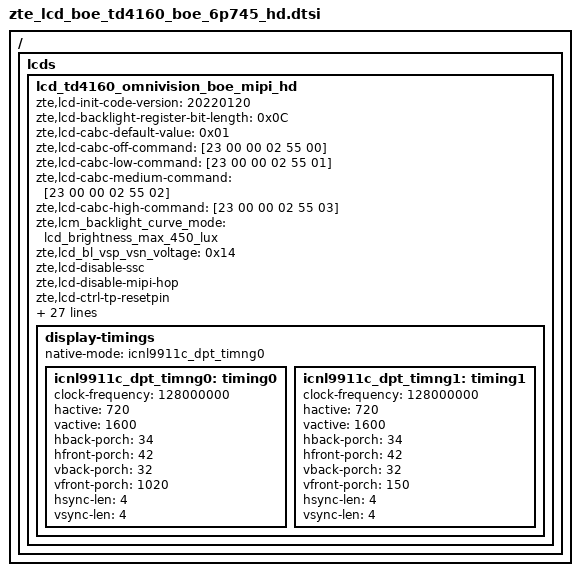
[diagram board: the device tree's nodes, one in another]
/ {
	fragment {
		target-path = "/";
		__overlay__ {
lcds {
		lcd_td4160_omnivision_boe_mipi_hd: lcd_td4160_omnivision_boe_mipi_hd {
			zte,lcd-init-code-version = "20220120";
			zte,lcd-backlight-register-bit-length = <0x0C>;
			zte,lcd-cabc-default-value = <0x01>;
			zte,lcd-cabc-off-command = [23 00 00 02 55 00];
			zte,lcd-cabc-low-command = [23 00 00 02 55 01];
			zte,lcd-cabc-medium-command = [23 00 00 02 55 02];
			zte,lcd-cabc-high-command = [23 00 00 02 55 03];
			zte,lcm_backlight_curve_mode = "lcd_brightness_max_450_lux";
			zte,lcd_bl_vsp_vsn_voltage = <0x14>;
			zte,lcd-disable-ssc;
			zte,lcd-disable-mipi-hop;
			zte,lcd-ctrl-tp-resetpin;
			zte,panel-name = "lcd_td4160_boe_6p745_mipi_hd_omnivision";
			zte,lcd-delay-open-bl-value = <30>;

			sprd,dsi-work-mode = <1>; /* video burst mode*/
			sprd,dsi-lane-number = <4>;
			sprd,dsi-color-format = "rgb888";

			sprd,phy-bit-clock = <768000>;	/* kbps */
			sprd,phy-escape-clock = <20000>;/* kHz */

			sprd,video-lp-cmd-enable = <1>;
			sprd,hporch-lp-disable = <1>;
			sprd,dpi-clk-div = <6>;

			sprd,width-mm = <70308>;
			sprd,height-mm = <156240>;

			sprd,esd-check-enable = <1>;/* 0:close , 1:open */
			sprd,esd-check-mode = <1>;/* 0:REG ,1:TE  */
			sprd,esd-check-period = <2000>;
			sprd,esd-check-register = <0x0A>;
			sprd,esd-check-value = <0x9C>;

			sprd,reset-on-sequence = <1 5>, <0 10>, <1 35>;
			sprd,reset-off-sequence = <0 5>;

			sprd,use-dcs-write;
			sprd,initial-command = [
				29 00 00 02 B0 04
				29 00 00 07 B6 30 6A 00 86 C3 03
				29 00 00 05 B7 31 00 00 00
				29 00 00 07 B8 00 78 64 10 64 B4
				29 00 00 07 B9 00 78 64 10 64 B4
				29 00 00 07 BA 07 7E 3E 10 1A 33
				29 00 00 04 BB 00 B4 A0
				29 00 00 04 BC 00 B4 A0
				29 00 00 04 BD 00 B4 A0
				29 00 00 0E BE 07 00 00 00 00 00 00 00 00
							00 00 00 00
				29 00 00 19 C0 00 60 24 06 40 00 16 06 98
							00 70 00 00 00 00 00 00 00 00
							00 00 00 00 00
				29 00 00 28 C1 30 11 50 FA 01 00 00 10 00
							00 00 00 40 0F 00 00 00 00 00
							00 00 00 00 00 00 00 00 00 00
							00 00 00 F0 07 08 07 D0 0A BE
				29 00 00 65 C2 01 20 50 14 04 10 0B 10 00
							00 00 00 00 00 00 00 00 00 00
							00 00 00 00 00 00 00 00 00 00
							00 00 00 00 00 00 00 00 00 00
							00 00 00 05 F0 54 08 08 05 05
							C5 00 80 00 00 00 00 08 00 00
							00 00 11 00 80 00 08 00 00 00
							00 00 00 00 00 00 00 00 00 00
							00 00 00 00 00 00 00 00 00 00
							00 00 00 00 11 00 00 00 00 00
							00
				29 00 00 65 C3 01 00 55 01 01 86 68 00 00
							00 20 01 01 00 55 01 01 86 68
							00 00 00 20 02 01 00 55 01 01
							86 68 00 00 00 20 00 01 00 55
							01 01 86 68 00 00 00 20 00 00
							00 00 08 00 00 00 00 00 00 00
							00 00 00 00 00 00 00 00 00 00
							00 00 00 00 00 00 00 00 00 00
							00 00 00 00 00 00 00 00 00 00
							00 00 00 00 00 00 00 00 00 00
							00
				29 00 00 55 C4 00 00 5E 64 00 03 05 13 15
							17 19 5D 5F 00 00 00 00 00 00
							00 00 00 00 00 00 00 00 00 00
							00 00 00 00 5F 5D 1A 18 16 14
							06 04 00 64 5E 00 00 00 00 00
							00 00 00 00 00 00 00 00 00 00
							00 00 00 00 00 00 00 00 00 00
							00 00 00 00 57 55 55 FF FF FF
							FF FF 55 55 D5
				29 00 00 06 C5 08 00 00 00 00
				29 00 00 4D C6 00 00 00 00 01 22 04 22 01
							00 61 00 00 00 01 00 61 00 01
							05 01 0B 01 35 FF 8F 06 05 01
							C0 0F 00 00 00 00 00 00 00 00
							00 00 00 00 00 00 00 00 00 00
							00 00 00 00 20 20 00 00 00 C0
							11 00 00 00 10 10 00 00 00 01
							00 50 00 33 03 00 00
				29 00 00 4D C7 00 00 00 79 00 B9 00 D3 00
							ED 00 FA 01 0A 01 0F 01 2E 01
							01 01 5C 01 22 01 6A 01 28 01
							99 01 A3 02 2D 02 96 02 A0 00
							00 00 79 00 B9 00 D3 00 ED 00
							FA 01 0A 01 0F 01 2E 01 01 01
							5C 01 22 01 6A 01 28 01 99 01
							A3 02 2D 02 96 02 A0
				29 00 00 1F CB 02 D0 01 80 00 00 00 00 00
							00 00 00 00 00 00 00 00 00 00
							00 00 00 40 70 00 00 00 00 00
							FF
				29 00 00 19 CE 5D 40 43 49 55 62 71 82 94
							A8 B9 CB DB E9 F5 FC FF 18 00
							04 04 00 04 8C
				29 00 00 02 CF 00
				29 00 00 15 D0 C1 46 81 66 09 90 00 CC F2
							FF 11 46 06 7E 09 08 CC 1B F0
							06
				29 00 00 26 D1 CE D8 1B 33 33 17 07 BB 33
							33 33 33 00 3B 77 07 3B 30 06
							72 33 13 00 D7 0C 33 02 00 18
							70 18 77 11 11 11 20 20
				29 00 00 04 D2 00 00 00
				29 00 00 65 D3 00 00 00 00 00 00 00 00 00
							FF F7 FF FF F7 FF FF F7 FF FF
							F7 FF FF F7 FF FF F7 FF FF F7
							FF FF F7 FF FF F7 FF FF F7 FF
							FF F7 FF FF F7 FF FF F7 FF FF
							F7 FF FF F7 FF FF F7 FF FF F7
							FF FF F7 FF FF F7 FF FF F7 FF
							FF F7 FF FF F7 FF FF F7 FF FF
							F7 FF FF F7 FF FF F7 FF FF F7
							FF FF F7 FF FF F7 FF FF F7 FF
							FF
				29 00 00 18 D4 00 00 00 00 00 00 00 00 00
							20 00 00 00 00 20 00 00 00 00
							00 00 00 00
				29 00 00 02 D6 00
				29 00 00 2F D7 01 00 12 12 00 62 00 16 00
							62 00 16 03 83 80 85 85 85 87
							84 45 86 87 80 88 86 89 83 83
							87 84 88 8A 0C 0B 0A 0A 0A 07
							07 06 06 00 08 0A 0A
				29 00 00 17 D8 40 99 26 ED 16 6C 16 6C 16
							6C 00 14 00 14 00 14 01 0C 00
							00 01 00
				29 00 00 29 D9 00 02 7F 00 00 00 00 00 00
							00 00 00 00 00 00 C0 00 00 00
							00 00 00 00 00 00 00 00 00 00
							00 00 00 00 00 00 00 00 00 00
							00
				29 00 00 05 DD 30 06 23 65
				29 00 00 0F DE 00 00 00 0F FF 00 00 00 00
							10 00 00 00 00
				29 00 00 05 E5 03 00 00 00
				29 00 00 09 E6 00 00 00 00 00 0E 00 00
				29 00 00 24 EA 02 07 07 04 80 10 01 00 00
							00 00 03 23 00 07 00 ED 00 ED
							00 ED 01 28 01 28 00 62 00 62
							00 62 01 0F 01 00
				29 00 00 09 EB 07 60 76 07 61 01 01 00
				29 00 00 18 EC 02 D0 01 70 73 10 01 00 00
							00 00 02 2A 00 00 00 00 00 00
							00 00 00 00
				29 00 00 22 ED 01 02 00 00 00 00 00 00 67
							A6 F0 00 00 00 00 00 00 00 00
							00 00 00 00 F0 01 00 00 00 00
							00 41 10 01
				29 00 00 65 EE 05 00 05 00 C0 0B 00 00 03
							00 00 03 00 00 03 00 C0 03 00
							00 00 00 00 00 03 00 00 00 00
							00 00 03 00 00 00 00 00 00 03
							00 00 00 00 00 00 03 00 40 17
							04 65 40 00 00 55 17 04 65 40
							00 00 55 17 04 65 40 00 00 40
							17 04 65 40 00 00 00 03 00 00
							03 00 00 03 00 00 03 00 00 03
							00 00 03 00 00 03 00 40 15 00
							00
				29 00 00 02 B0 03

				29 00 00 03 51 00 00
				29 00 00 02 53 2C
				29 00 00 02 55 00
				29 00 00 02 35 00

				05 78 00 01 11
				05 32 00 01 29
				];

			sprd,sleep-in-command = [
				15 0A 00 01 28
				15 78 00 01 10
				];

			sprd,sleep-out-command = [
				15 78 00 01 11
				15 32 00 01 29
				];

			display-timings {
				native-mode = <&icnl9911c_dpt_timng0>;
				icnl9911c_dpt_timng0: timing0 {
					clock-frequency = <128000000>;
					hactive = <720>;
					vactive = <1600>;
					hback-porch = <34>;
					hfront-porch = <42>;
					vback-porch = <32>;
					vfront-porch = <1020>;
					hsync-len = <4>;
					vsync-len = <4>;
				};
				icnl9911c_dpt_timng1: timing1 {
					clock-frequency = <128000000>;
					hactive = <720>;
					vactive = <1600>;
					hback-porch = <34>;
					hfront-porch = <42>;
					vback-porch = <32>;
					vfront-porch = <150>;
					hsync-len = <4>;
					vsync-len = <4>;
				};
			};
		};
	};
};
};};
